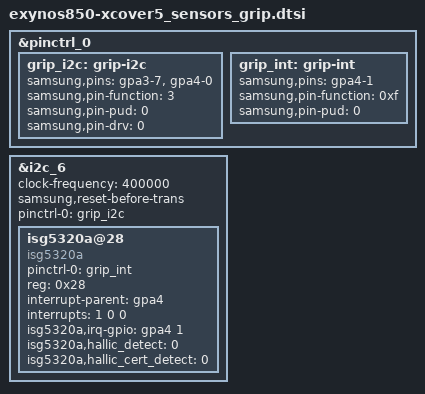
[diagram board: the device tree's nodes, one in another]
&pinctrl_0 {
	grip_i2c: grip-i2c {
		samsung,pins = "gpa3-7", "gpa4-0";
		samsung,pin-function = <3>;
		samsung,pin-pud = <0>;
		samsung,pin-drv = <0>;
	};

	grip_int: grip-int {
		samsung,pins = "gpa4-1";
		samsung,pin-function = <0xf>;
		samsung,pin-pud = <0>;
	};
};

&i2c_6 {
	#address-cells = <1>;
	#size-cells = <0>;
	status = "okay";
	clock-frequency = <400000>;
	samsung,reset-before-trans;
	pinctrl-names = "default";
	pinctrl-0 = <&grip_i2c>;

	isg5320a@28 {
		compatible = "isg5320a";
		pinctrl-names = "default";
		pinctrl-0 = <&grip_int>;
		reg = <0x28>;
		status = "okay";
		interrupt-parent = <&gpa4>;
		interrupts = <1 0 0>;

		isg5320a,irq-gpio = <&gpa4 1 0x00>;
		isg5320a,hallic_detect = <0>;
		isg5320a,hallic_cert_detect = <0>;
	};
};
